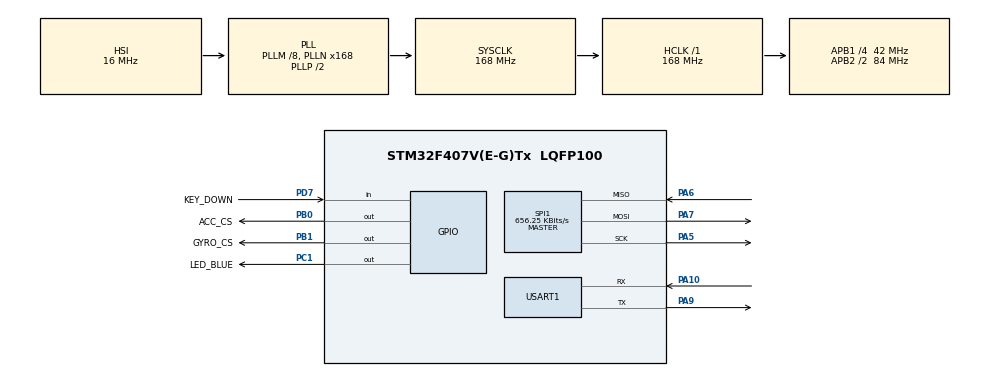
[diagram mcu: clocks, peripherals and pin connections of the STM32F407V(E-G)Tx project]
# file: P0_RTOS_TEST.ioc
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FREERTOS.Queues01=BtnQueue,16,uint32_t,0,Dynamic,NULL,NULL;IMU_Data,16,IMU_Data_t*,0,Dynamic,NULL,NULL
FREERTOS.Tasks01=LED_Task,24,128,Start_LED_Task,As weak,NULL,Dynamic,NULL,NULL;Serial_1_Task,8,128,Start_Serial_1_Task,As external,NULL,Dynamic,NULL,NULL;Btn_Task,24,128,StartTaskBtn,As external,NULL,Dynamic,NULL,NULL;IMU_Task,8,256,Start_IMU_Task,As external,NULL,Dynamic,NULL,NULL
Mcu.Family=STM32F4
Mcu.Name=STM32F407V(E-G)Tx
Mcu.Package=LQFP100
NVIC.PriorityGroup=NVIC_PRIORITYGROUP_4
NVIC.TIM4_IRQn=true\:15\:0\:false\:false\:true\:false\:false\:true\:true
NVIC.TimeBase=TIM4_IRQn
NVIC.TimeBaseIP=TIM4
PA10.Mode=Asynchronous
PA10.Signal=USART1_RX
PA13.Mode=Serial_Wire
PA13.Signal=SYS_JTMS-SWDIO
PA14.Mode=Serial_Wire
PA14.Signal=SYS_JTCK-SWCLK
PA5.Mode=Full_Duplex_Master
PA5.Signal=SPI1_SCK
PA6.Mode=Full_Duplex_Master
PA6.Signal=SPI1_MISO
PA7.Mode=Full_Duplex_Master
PA7.Signal=SPI1_MOSI
PA9.Mode=Asynchronous
PA9.Signal=USART1_TX
PB0.GPIO_Label=ACC_CS
PB0.GPIO_PuPd=GPIO_PULLUP
PB0.Signal=GPIO_Output
PB1.GPIO_Label=GYRO_CS
PB1.GPIO_PuPd=GPIO_PULLUP
PB1.Signal=GPIO_Output
PC1.GPIO_Label=LED_BLUE
PC1.Signal=GPIO_Output
PC14-OSC32_IN.Mode=LSE-External-Oscillator
PC14-OSC32_IN.Signal=RCC_OSC32_IN
PC15-OSC32_OUT.Mode=LSE-External-Oscillator
PC15-OSC32_OUT.Signal=RCC_OSC32_OUT
PD7.GPIO_Label=KEY_DOWN
PD7.GPIO_PuPd=GPIO_PULLUP
PD7.Signal=GPIO_Input
PH0-OSC_IN.Mode=HSE-External-Oscillator
PH0-OSC_IN.Signal=RCC_OSC_IN
PH1-OSC_OUT.Mode=HSE-External-Oscillator
PH1-OSC_OUT.Signal=RCC_OSC_OUT
ProjectManager.HeapSize=0x200
ProjectManager.StackSize=0x400
ProjectManager.TargetToolchain=CMake
RCC.48MHZClocksFreq_Value=84000000
RCC.AHBFreq_Value=168000000
RCC.APB1CLKDivider=RCC_HCLK_DIV4
RCC.APB1Freq_Value=42000000
RCC.APB1TimFreq_Value=84000000
RCC.APB2CLKDivider=RCC_HCLK_DIV2
RCC.APB2Freq_Value=84000000
RCC.APB2TimFreq_Value=168000000
RCC.CortexFreq_Value=168000000
RCC.HCLKFreq_Value=168000000
RCC.HSE_VALUE=8000000
RCC.HSI_VALUE=16000000
RCC.PLLM=8
RCC.PLLN=168
RCC.SYSCLKFreq_VALUE=168000000
RCC.SYSCLKSource=RCC_SYSCLKSOURCE_PLLCLK
RCC.VCOOutputFreq_Value=336000000
SPI1.BaudRatePrescaler=SPI_BAUDRATEPRESCALER_128
SPI1.CalculateBaudRate=656.25 KBits/s
SPI1.Direction=SPI_DIRECTION_2LINES
SPI1.Mode=SPI_MODE_MASTER
SPI1.VirtualType=VM_MASTER
USART1.VirtualMode=VM_ASYNC
VP_FREERTOS_VS_CMSIS_V2.Mode=CMSIS_V2
VP_SYS_VS_tim4.Mode=TIM4
board=custom

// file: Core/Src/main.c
/* USER CODE BEGIN Header */
/**
  ******************************************************************************
  * @file           : main.c
  * @brief          : Main program body
  ******************************************************************************
  * @attention
  *
  * Copyright (c) 2026 STMicroelectronics.
  * All rights reserved.
  *
  * This software is licensed under terms that can be found in the LICENSE file
  * in the root directory of this software component.
  * If no LICENSE file comes with this software, it is provided AS-IS.
  *
  ******************************************************************************
  */
/* USER CODE END Header */
#include "main.h"
#include "cmsis_os.h"
#include "spi.h"
#include "usart.h"
#include "gpio.h"

/* USER CODE BEGIN Includes */
#include "Inc/app_imu.h"

/* USER CODE END Includes */

void SystemClock_Config(void);
void MX_FREERTOS_Init(void);

int main(void)
{

  /* MCU Configuration--------------------------------------------------------*/

  /* Reset of all peripherals, Initializes the Flash interface and the Systick. */
  HAL_Init();

  /* Configure the system clock */
  SystemClock_Config();

  /* Initialize all configured peripherals */
  MX_GPIO_Init();
  MX_USART1_UART_Init();
  MX_SPI1_Init();
  /* USER CODE BEGIN 2 */
  APP_IMU_Init();
  /* USER CODE END 2 */

  /* Init scheduler */
  osKernelInitialize();  /* Call init function for freertos objects (in cmsis_os2.c) */
  MX_FREERTOS_Init();

  /* Start scheduler */
  osKernelStart();

  /* We should never get here as control is now taken by the scheduler */

  /* Infinite loop */
  while (1)
  {

  }
}

void SystemClock_Config(void)
{
  RCC_OscInitTypeDef RCC_OscInitStruct = {0};
  RCC_ClkInitTypeDef RCC_ClkInitStruct = {0};

  /** Configure the main internal regulator output voltage
  */
  __HAL_RCC_PWR_CLK_ENABLE();
  __HAL_PWR_VOLTAGESCALING_CONFIG(PWR_REGULATOR_VOLTAGE_SCALE1);

  /** Initializes the RCC Oscillators according to the specified parameters
  * in the RCC_OscInitTypeDef structure.
  */
  RCC_OscInitStruct.OscillatorType = RCC_OSCILLATORTYPE_HSI;
  RCC_OscInitStruct.HSIState = RCC_HSI_ON;
  RCC_OscInitStruct.HSICalibrationValue = RCC_HSICALIBRATION_DEFAULT;
  RCC_OscInitStruct.PLL.PLLState = RCC_PLL_ON;
  RCC_OscInitStruct.PLL.PLLSource = RCC_PLLSOURCE_HSI;
  RCC_OscInitStruct.PLL.PLLM = 8;
  RCC_OscInitStruct.PLL.PLLN = 168;
  RCC_OscInitStruct.PLL.PLLP = RCC_PLLP_DIV2;
  RCC_OscInitStruct.PLL.PLLQ = 4;
  if (HAL_RCC_OscConfig(&RCC_OscInitStruct) != HAL_OK)
  {
    Error_Handler();
  }

  /** Initializes the CPU, AHB and APB buses clocks
  */
  RCC_ClkInitStruct.ClockType = RCC_CLOCKTYPE_HCLK|RCC_CLOCKTYPE_SYSCLK
                              |RCC_CLOCKTYPE_PCLK1|RCC_CLOCKTYPE_PCLK2;
  RCC_ClkInitStruct.SYSCLKSource = RCC_SYSCLKSOURCE_PLLCLK;
  RCC_ClkInitStruct.AHBCLKDivider = RCC_SYSCLK_DIV1;
  RCC_ClkInitStruct.APB1CLKDivider = RCC_HCLK_DIV4;
  RCC_ClkInitStruct.APB2CLKDivider = RCC_HCLK_DIV2;

  if (HAL_RCC_ClockConfig(&RCC_ClkInitStruct, FLASH_LATENCY_5) != HAL_OK)
  {
    Error_Handler();
  }
}

void HAL_TIM_PeriodElapsedCallback(TIM_HandleTypeDef *htim)
{
  if (htim->Instance == TIM4)
  {
    HAL_IncTick();
  }
}

void Error_Handler(void)
{
  __disable_irq();
  while (1)
  {
  }
}

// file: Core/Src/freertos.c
/* USER CODE BEGIN Header */
/**
  ******************************************************************************
  * File Name          : freertos.c
  * Description        : Code for freertos applications
  ******************************************************************************
  * @attention
  *
  * Copyright (c) 2026 STMicroelectronics.
  * All rights reserved.
  *
  * This software is licensed under terms that can be found in the LICENSE file
  * in the root directory of this software component.
  * If no LICENSE file comes with this software, it is provided AS-IS.
  *
  ******************************************************************************
  */
/* USER CODE END Header */

#include "FreeRTOS.h"
#include "task.h"
#include "main.h"
#include "cmsis_os.h"

/* USER CODE BEGIN Includes */
#include "string.h"
#include "usart.h"
#include "gpio.h"
#include <stdint.h>
#include <stdio.h>
#include "Inc/app_imu.h"
/* USER CODE END Includes */

/* Definitions for LED_Task */
osThreadId_t LED_TaskHandle;
const osThreadAttr_t LED_Task_attributes = {
  .name = "LED_Task",
  .stack_size = 128 * 4,
  .priority = (osPriority_t) osPriorityNormal,
};
/* Definitions for Serial_1_Task */
osThreadId_t Serial_1_TaskHandle;
const osThreadAttr_t Serial_1_Task_attributes = {
  .name = "Serial_1_Task",
  .stack_size = 128 * 4,
  .priority = (osPriority_t) osPriorityLow,
};
/* Definitions for Btn_Task */
osThreadId_t Btn_TaskHandle;
const osThreadAttr_t Btn_Task_attributes = {
  .name = "Btn_Task",
  .stack_size = 128 * 4,
  .priority = (osPriority_t) osPriorityNormal,
};
/* Definitions for IMU_Task */
osThreadId_t IMU_TaskHandle;
const osThreadAttr_t IMU_Task_attributes = {
  .name = "IMU_Task",
  .stack_size = 256 * 4,
  .priority = (osPriority_t) osPriorityLow,
};
/* Definitions for BtnQueue */
osMessageQueueId_t BtnQueueHandle;
const osMessageQueueAttr_t BtnQueue_attributes = {
  .name = "BtnQueue"
};
/* Definitions for IMU_Data */
osMessageQueueId_t IMU_DataHandle;
const osMessageQueueAttr_t IMU_Data_attributes = {
  .name = "IMU_Data"
};

void Start_LED_Task(void *argument);
extern void Start_Serial_1_Task(void *argument);
extern void StartTaskBtn(void *argument);
extern void Start_IMU_Task(void *argument);

void MX_FREERTOS_Init(void); /* (MISRA C 2004 rule 8.1) */

void MX_FREERTOS_Init(void) {

  /* Create the queue(s) */
  /* creation of BtnQueue */
  BtnQueueHandle = osMessageQueueNew (16, sizeof(uint32_t), &BtnQueue_attributes);

  /* creation of IMU_Data */
  IMU_DataHandle = osMessageQueueNew (16, sizeof(IMU_Data_t*), &IMU_Data_attributes);

  /* Create the thread(s) */
  /* creation of LED_Task */
  LED_TaskHandle = osThreadNew(Start_LED_Task, NULL, &LED_Task_attributes);

  /* creation of Serial_1_Task */
  Serial_1_TaskHandle = osThreadNew(Start_Serial_1_Task, NULL, &Serial_1_Task_attributes);

  /* creation of Btn_Task */
  Btn_TaskHandle = osThreadNew(StartTaskBtn, NULL, &Btn_Task_attributes);

  /* creation of IMU_Task */
  IMU_TaskHandle = osThreadNew(Start_IMU_Task, NULL, &IMU_Task_attributes);

}

__weak void Start_LED_Task(void *argument)
{
  for(;;)
  {
  }
}
